# ATSAME53J18A device description
Architecture: CORTEX-M4; Family: SAME; Series: SAME53
Registers are 32-bit, read-write, reset 0x0 unless marked. A register's access mark holds for its fields unless they carry their own. Offsets are from the block's base; [hi:lo] are bit positions; {n}, {i} and the like mark numbered series; 'fields as' and 'values as' point back to an identical list.

## WDT — Watchdog Timer
Instances: WDT 0x40002000
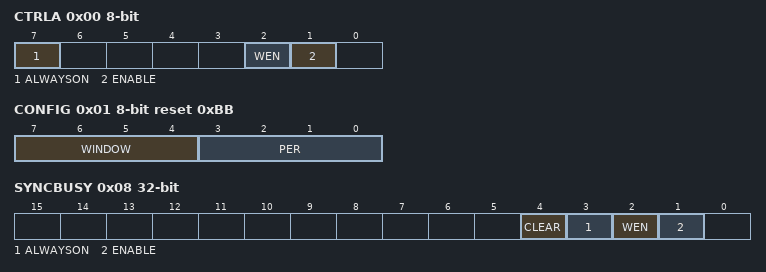
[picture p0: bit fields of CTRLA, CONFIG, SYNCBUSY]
0x00 CTRLA 8-bit (WSYNC) — Control
  [7] ALWAYSON
  [2] WEN — Watchdog Timer Window Mode Enable
  [1] ENABLE
0x01 CONFIG 8-bit reset 0xBB — Configuration
  [7:4] WINDOW — Window Mode Time-Out Period
    0=CYC8 (8 clock cycles); 1=CYC16 (16 clock cycles); 2=CYC32 (32 clock cycles); 3=CYC64 (64 clock cycles); 4=CYC128 (128 clock cycles); 5=CYC256 (256 clock cycles); 6=CYC512 (512 clock cycles); 7=CYC1024 (1024 clock cycles); 8=CYC2048 (2048 clock cycles); 9=CYC4096 (4096 clock cycles); 10=CYC8192 (8192 clock cycles); 11=CYC16384 (16384 clock cycles)
  [3:0] PER — Time-Out Period
    values as WINDOW
0x02 EWCTRL 8-bit reset 0xB — Early Warning Interrupt Control
  [3:0] EWOFFSET — Early Warning Interrupt Time Offset
    values as CONFIG.WINDOW
0x04 INTENCLR 8-bit (atomic clear) — Interrupt Enable Clear
  [0] EW — Early Warning Interrupt Enable
0x05 INTENSET 8-bit (atomic set) — Interrupt Enable Set
  [0] EW — Early Warning Interrupt Enable
0x06 INTFLAG 8-bit (atomic clear) — Interrupt Flag Status and Clear
  [0] EW — Early Warning
0x08 SYNCBUSY ro — Synchronization Busy
  [4] CLEAR — Clear Synchronization Busy
  [3] ALWAYSON — Always-On Synchronization Busy
  [2] WEN — Window Enable Synchronization Busy
  [1] ENABLE — Enable Synchronization Busy
0x0C CLEAR 8-bit wo (WSYNC)
  [7:0] CLEAR — Watchdog Clear
    165=KEY (Clear Key)

## CoreDebug
Instances: CoreDebug 0xE000EDF0
0x00 DHCSR reset not defined — Debug Halting Control and Status Register
  [25] S_RESET_ST, [24] S_RETIRE_ST, [19] S_LOCKUP, [18] S_SLEEP, [17] S_HALT, [16] S_REGRDY, [31:16] DBGKEY, [5] C_SNAPSTALL, [3] C_MASKINTS, [2] C_STEP, [1] C_HALT, [0] C_DEBUGEN
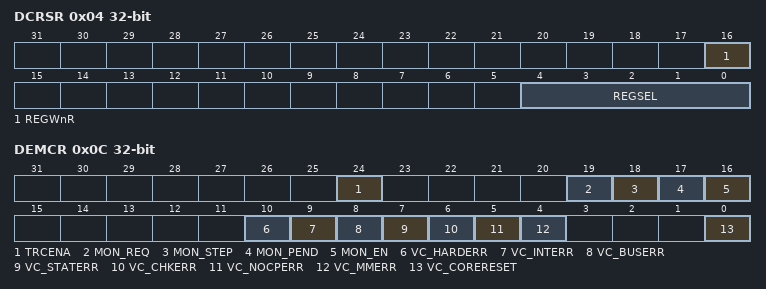
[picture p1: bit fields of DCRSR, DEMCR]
0x04 DCRSR wo reset not defined — Debug Core Register Selector Register
  [16] REGWnR, [4:0] REGSEL
0x08 DCRDR reset not defined — Debug Core Register Data Register
0x0C DEMCR reset not defined — Debug Exception and Monitor Control Register
  [24] TRCENA, [19] MON_REQ, [18] MON_STEP, [17] MON_PEND, [16] MON_EN, [10] VC_HARDERR, [9] VC_INTERR, [8] VC_BUSERR, [7] VC_STATERR, [6] VC_CHKERR, [5] VC_NOCPERR, [4] VC_MMERR, [0] VC_CORERESET

## DWT — Data Watchpoint and Trace Register
Instances: DWT 0xE0001000
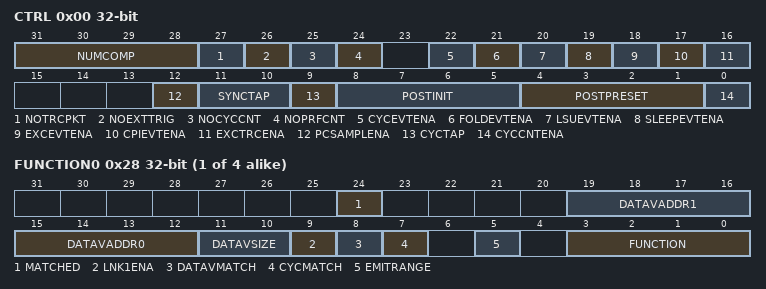
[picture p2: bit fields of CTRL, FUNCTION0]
0x00 CTRL reset not defined — Control Register
  [31:28] NUMCOMP, [27] NOTRCPKT, [26] NOEXTTRIG, [25] NOCYCCNT, [24] NOPRFCNT, [22] CYCEVTENA, [21] FOLDEVTENA, [20] LSUEVTENA, [19] SLEEPEVTENA, [18] EXCEVTENA, [17] CPIEVTENA, [16] EXCTRCENA, [12] PCSAMPLENA, [11:10] SYNCTAP, [9] CYCTAP, [8:5] POSTINIT, [4:1] POSTPRESET, [0] CYCCNTENA
0x04 CYCCNT reset not defined — Cycle Count Register
0x08 CPICNT reset not defined — CPI Count Register
  [7:0] CPICNT
0x0C EXCCNT reset not defined — Exception Overhead Count Register
  [7:0] EXCCNT
0x10 SLEEPCNT reset not defined — Sleep Count Register
  [7:0] SLEEPCNT
0x14 LSUCNT reset not defined — LSU Count Register
  [7:0] LSUCNT
0x18 FOLDCNT reset not defined — Folded-instruction Count Register
  [7:0] FOLDCNT
0x1C PCSR ro reset not defined — Program Counter Sample Register
{0x20+0x10*i} COMP{i} reset not defined (i=0..3) — Comparator Register {i}
{0x24+0x10*i} MASK{i} reset not defined (i=0..3) — Mask Register {i}
  [4:0] MASK
{0x28+0x10*i} FUNCTION{i} reset not defined (i=0..3) — Function Register {i}
  [24] MATCHED, [19:16] DATAVADDR1, [15:12] DATAVADDR0, [11:10] DATAVSIZE, [9] LNK1ENA, [8] DATAVMATCH, [7] CYCMATCH, [5] EMITRANGE, [3:0] FUNCTION

## ETM — Embedded Trace Macrocell
Instances: ETM 0xE0041000
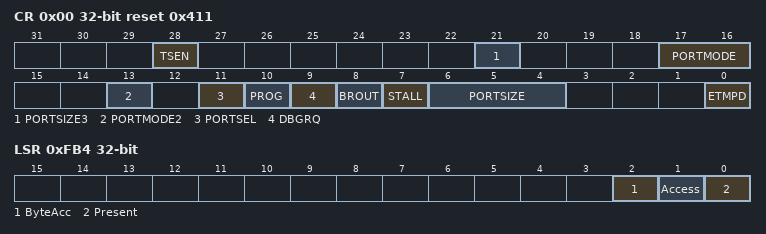
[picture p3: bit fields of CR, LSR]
0x00 CR reset 0x411 — ETM Main Control Register
  [28] TSEN — TimeStamp Enable
  [21] PORTSIZE3 — Port Size bit 3
  [17:16] PORTMODE — Port Mode bits 1:0
  [13] PORTMODE2 — Port Mode bit 2
  [11] PORTSEL — ETM Port Select
  [10] PROG — ETM Programming
  [9] DBGRQ — Debug Request Control
  [8] BROUT — Branch Output
  [7] STALL — Stall Processor
  [6:4] PORTSIZE — Port Size bits 2:0
  [0] ETMPD — ETM Power Down
0x04 CCR ro reset 0x8C802000 — ETM Configuration Code Register
0x08 TRIGGER reset not defined — ETM Trigger Event Register
0x10 SR reset not defined — ETM Status Register
0x14 SCR ro reset 0x20D09 (atomic clear of SR) — ETM System Configuration Register
0x20 TEEVR reset not defined — ETM TraceEnable Event Register
0x24 TECR1 reset not defined — ETM TraceEnable Control 1 Register
0x28 FFLR reset not defined — ETM FIFO Full Level Register
0x140 CNTRLDVR1 reset not defined — ETM Free-running Counter Reload Value
0x1E0 SYNCFR ro reset 0x400 — ETM Synchronization Frequency Register
0x1E4 IDR ro reset 0x4114F250 — ETM ID Register
0x1E8 CCER ro reset 0x18541800 — ETM Configuration Code Extension Register
0x1F0 TESSEICR reset not defined — ETM TraceEnable Start/Stop EmbeddedICE Control Register
0x1F8 TSEVT reset not defined — ETM TimeStamp Event Register
0x200 TRACEIDR — ETM CoreSight Trace ID Register
0x208 IDR2 ro — ETM ID Register 2
0x314 PDSR ro reset 0x1 — ETM Device Power-Down Status Register
0xEE0 ITMISCIN ro reset not defined — ETM Integration Test Miscellaneous Inputs
0xEE8 ITTRIGOUT wo reset not defined — ETM Integration Test Trigger Out
0xEF0 ITATBCTR2 ro reset not defined — ETM Integration Test ATB Control 2
0xEF8 ITATBCTR0 wo reset not defined — ETM Integration Test ATB Control 0
0xF00 ITCTRL — ETM Integration Mode Control Register
  [0] INTEGRATION
0xFA0 CLAIMSET reset not defined (atomic set) — ETM Claim Tag Set Register
0xFA4 CLAIMCLR reset not defined (atomic clear) — ETM Claim Tag Clear Register
0xFB0 LAR wo reset not defined — ETM Lock Access Register
0xFB4 LSR ro reset not defined — ETM Lock Status Register
  [2] ByteAcc, [1] Access, [0] Present
0xFB8 AUTHSTATUS ro reset not defined — ETM Authentication Status Register
0xFCC DEVTYPE ro reset 0x13 — ETM CoreSight Device Type Register
0xFD0 PIDR4 ro reset 0x4 — ETM Peripheral Identification Register #4
{0xFC0+4i} PIDR{i} ro (i=5..7) — ETM Peripheral Identification Register #{i}
0xFE0 PIDR0 ro reset 0x25 — ETM Peripheral Identification Register #0
0xFE4 PIDR1 ro reset 0xB9 — ETM Peripheral Identification Register #1
0xFE8 PIDR2 ro reset 0xB — ETM Peripheral Identification Register #2
0xFEC PIDR3 ro — ETM Peripheral Identification Register #3
0xFF0 CIDR0 ro reset 0xD — ETM Component Identification Register #0
0xFF4 CIDR1 ro reset 0x90 — ETM Component Identification Register #1
0xFF8 CIDR2 ro reset 0x5 — ETM Component Identification Register #2
0xFFC CIDR3 ro reset 0xB1 — ETM Component Identification Register #3

## Notices in the file
Copyright (c) 2018 Microchip Technology Inc.
SPDX-License-Identifier: Apache-2.0
Licensed under the Apache License, Version 2.0 (the "License");
you may not use this file except in compliance with the License.
You may obtain a copy of the License at
http://www.apache.org/licenses/LICENSE-2.0
Unless required by applicable law or agreed to in writing, software
distributed under the License is distributed on an "AS IS" BASIS,
WITHOUT WARRANTIES OR CONDITIONS OF ANY KIND, either express or implied.
See the License for the specific language governing permissions and
limitations under the License.
